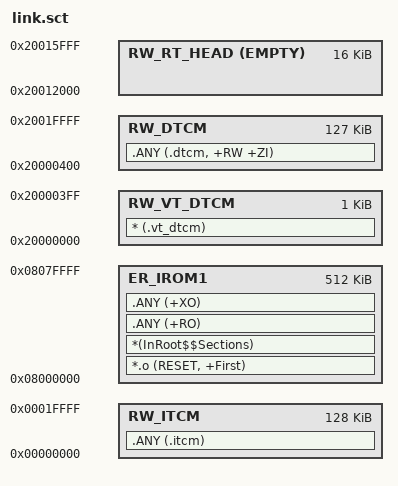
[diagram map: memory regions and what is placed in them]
; *************************************************************
; *** Scatter-Loading Description File generated by uVision ***
; *************************************************************

LR_IROM1 0x08000000 0x00080000  {    ; load region size_region
  ER_IROM1 0x08000000 0x00080000  {  ; load address = execution address
    *.o (RESET, +First)
    *(InRoot$$Sections)
    .ANY (+RO)
    .ANY (+XO)
  }

  RW_ITCM 0x00000000 0x00020000  {  ; 128K ITCM -> code in sram
    .ANY (.itcm)
  }

  RW_VT_DTCM 0x20000000 0x00000400  {  ; 1K VT_DTCM -> Vector Table
    * (.vt_dtcm)
  }

  RW_DTCM 0x20000400 0x0001FC00    {  ; 127K DTCM -> fast sram
    .ANY (.dtcm, +RW +ZI)
;    startup_*.o(STACK)
;    startup_*.o(HEAP)
  }

  RW_RT_HEAD 0x20012000 EMPTY 0x4000 {

  }

;  RW_SRAM1 0x20100000 0x00020000  {  ; sram with ECC
;    * (.sram1)
;  }

;  RW_SRAM2 0x20120000 0x00020000  {  ; sram with ECC
;    * (.sram2)
;  }

;  RW_SRAMB 0x400B7000 UNINIT 0x00001000  {  ; sram with backup
;    * (.bss.bkupsram)
;  }
}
